# SN32F700 register map
Vendor: SONiX Technology Co., Ltd.; Series: SN32F700; File version: 1.9
CPU: CM0 r0p0, little endian, no MPU, no FPU, 2 interrupt priority bits
Registers are 32-bit, read-write, reset 0x0 unless marked. A register's access mark holds for its fields unless they carry their own. Offsets are from the block's base; [hi:lo] are bit positions; {n}, {i} and the like mark numbered series.

## SN_ADC — ADC
Base 0x40026000
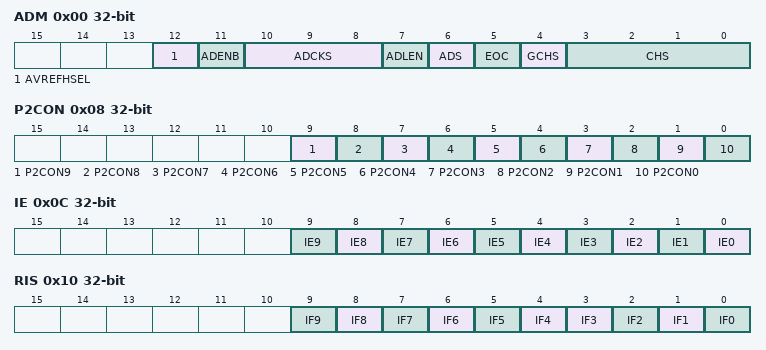
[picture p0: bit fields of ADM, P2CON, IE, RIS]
0x00 ADM (reset mask 0xFFF) — Offset:0x00 ADC Management Register
  [12] AVREFHSEL — ADC high reference voltage source
    0=Interal VDD (P2.0 acts as GPIO or AIN0 pin); 1=External reference voltage (P2.0 acts as AVREFH pin)
  [11] ADENB — ADC enable
    0=Disable ADC; 1=Enable ADC
  [10:8] ADCKS — ADC clock source divider
    0=000b (ADC_PCLK/1); 1=001b (ADC_PCLK/2); 2=010b (ADC_PCLK/4); 3=011b (ADC_PCLK/8); 5=101b (ADC_PCLK/16); 6=110b (ADC_PCLK/32)
  [7] ADLEN — ADC resolution
    0=8-bit ADB; 1=12-bit ADB
  [6] ADS — ADC start control
    0=Stop (ADC stopped); 1=Start ADC conversion
  [5] EOC — ADC status
    0=Busy (ADC processing); 1=End (End of conversion)
  [4] GCHS — ADC global channel enable
    0=Disable AIN channel; 1=Enable AIN channel
  [3:0] CHS — ADC input channel
    {v}=AIN{v} (v=0..9)
0x04 ADB ro (reset mask 0xFFF) — Offset:0x04 ADC Data Register
0x08 P2CON (reset mask 0x1FF) — Offset:0x08 ADC Port 2 Control Register
  [9] P2CON9 — P2.9 Control
    0=Both (P2.9 can be analog input or digital I/O pin); 1=Analog (P2.9 is pure analog input, can't be digital I/O pin)
  [8] P2CON8 — P2.8 Control
    0=Both (P2.8 can be analog input or digital I/O pin); 1=Analog (P2.8 is pure analog input, can't be digital I/O pin)
  [7] P2CON7 — P2.7 Control
    0=Both (P2.7 can be analog input or digital I/O pin); 1=Analog (P2.7 is pure analog input, can't be digital I/O pin)
  [6] P2CON6 — P2.6 Control
    0=Both (P2.6 can be analog input or digital I/O pin); 1=Analog (P2.6 is pure analog input, can't be digital I/O pin)
  [5] P2CON5 — P2.5 Control
    0=Both (P2.5 can be analog input or digital I/O pin); 1=Analog (P2.5 is pure analog input, can't be digital I/O pin)
  [4] P2CON4 — P2.4 Control
    0=Both (P2.4 can be analog input or digital I/O pin); 1=Analog (P2.4 is pure analog input, can't be digital I/O pin)
  [3] P2CON3 — P2.3 Control
    0=Both (P2.3 can be analog input or digital I/O pin); 1=Analog (P2.3 is pure analog input, can't be digital I/O pin)
  [2] P2CON2 — P2.2 Control
    0=Both (P2.2 can be analog input or digital I/O pin); 1=Analog (P2.2 is pure analog input, can't be digital I/O pin)
  [1] P2CON1 — P2.1 Control
    0=Both (P2.1 can be analog input or digital I/O pin); 1=Analog (P2.1 is pure analog input, can't be digital I/O pin)
  [0] P2CON0 — P2.0 Control
    0=Both (P2.0 can be analog input or digital I/O pin); 1=Analog (P2.0 is pure analog input, can't be digital I/O pin)
0x0C IE (reset mask 0x1FF) — Offset:0x0C ADC Interrupt Enable Register
  [n] IE{n} (n=0..9) — AIN{n} interrupt enable
    0=Disable AIN{n} interrupt; 1=Enable (ADC interrupt is triggered when AIN{n} completes ADC conversion)
0x10 RIS (reset mask 0x1F) — Offset:0x10 ADC Raw Interrupt Status Register
  [n] IF{n} (n=4..9) — AIN{n} interrupt flag
    0=No interrupt on AIN{n}; 1=Met interrupt requirements (AIN{n} completes ADC conversion)
  [3] IF3 — AIN0 interrupt flag
    0=No interrupt on AIN3; 1=Met interrupt requirements (AIN3 completes ADC conversion)
  [2] IF2 — AIN2 interrupt flag
    0=No interrupt on AIN2; 1=Met interrupt requirements (AIN2 completes ADC conversion)
  [1] IF1 — AIN1 interrupt flag
    0=No interrupt on AIN1; 1=Met interrupt requirements (AIN1 completes ADC conversion)
  [0] IF0 — AIN0 interrupt flag
    0=No interrupt on AIN0; 1=Met interrupt requirements (AIN0 completes ADC conversion)
0x14 CALI (reset mask 0xF) — Offset:0x14 ADC Calibration Register

## SN_WDT — Watchdog Timer
Base 0x40010000
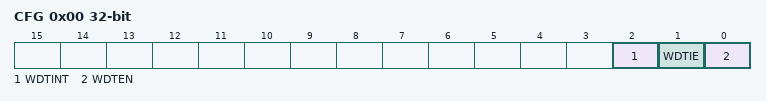
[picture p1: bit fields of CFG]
0x00 CFG — Offset:0x00 WDT Configuration Register
  [2] WDTINT — WDT interrupt flag
    0=No (No WDT time-out); 1=WDT time-out (WDT interrupt is triggered if WDTIE=1)
  [1] WDTIE — WDT interrupt enable
    0=Disable (WDT reset when WDT time-out); 1=Enable WDT interrupt
  [0] WDTEN — WDT enable
    0=Disable WDT; 1=Enable WDT
0x04 CLKSOURCE — Offset:0x04 WDT Clock Source Register
  [1:0] CLKSEL — WDT clock source
    0=IHRC (WDT clock source=IHRC); 1=HCLK (WDT clock source=HCLK); 2=ILRC (WDT clock source=ILRC); 3=ELS XTAL (WDT clock source=ELS XTAL)
0x08 TC reset 0xFF — Offset:0x08 WDT Timer Constant Register
  [7:0] TC — Watchdog timer constant reload value
0x0C FEED wo — Offset:0x0C WDT Feed Register
  [15:0] FV — Watchdog feed value
